# STM32MP157 register map
File version: 1.7
CPU: CM4 r0p1, little endian, no MPU, FPU, 4 interrupt priority bits
Registers are 32-bit, read-write, reset 0x0 unless marked. A register's access mark holds for its fields unless they carry their own. Offsets are from the block's base; [hi:lo] are bit positions; {n}, {i} and the like mark numbered series.

## GPIOA
Base 0x50002000
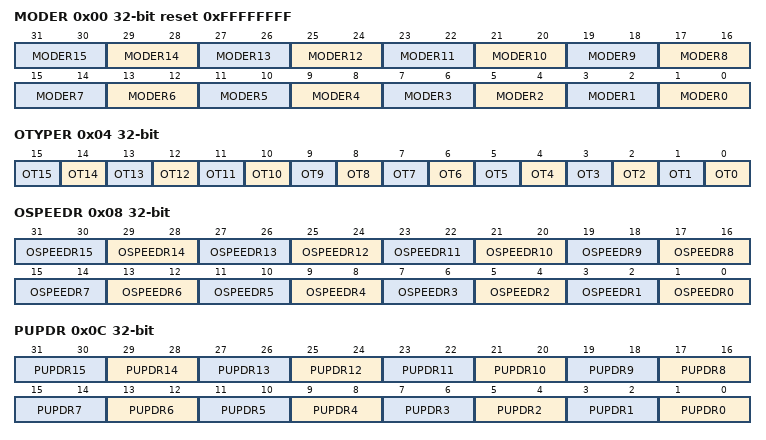
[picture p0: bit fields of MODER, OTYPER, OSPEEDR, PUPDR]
0x00 MODER reset 0xFFFFFFFF — GPIO port mode register
  [2n+1:2n] MODER{n} (n=0..15) — Port x configuration pin {n}
    0=Input mode (reset state); 1=Output (General purpose output mode); 2=Alternate function mode; 3=Analog mode
0x04 OTYPER — GPIO port output type register
  [n] OT{n} (n=0..15) — Port x configuration pin {n}
    0=PushPull (Output push-pull (reset state)); 1=OpenDrain (Output open-drain)
0x08 OSPEEDR — GPIO port output speed register
  [2n+1:2n] OSPEEDR{n} (n=0..15) — Port x configuration pin {n}
    0=LowSpeed; 1=MediumSpeed; 2=HighSpeed; 3=VeryHighSpeed
0x0C PUPDR — GPIO port pull-up/pull-down register
  [2n+1:2n] PUPDR{n} (n=0..15) — Port x configuration pin {n}
    0=Floating (No pull-up, pull-down); 1=PullUp; 2=PullDown
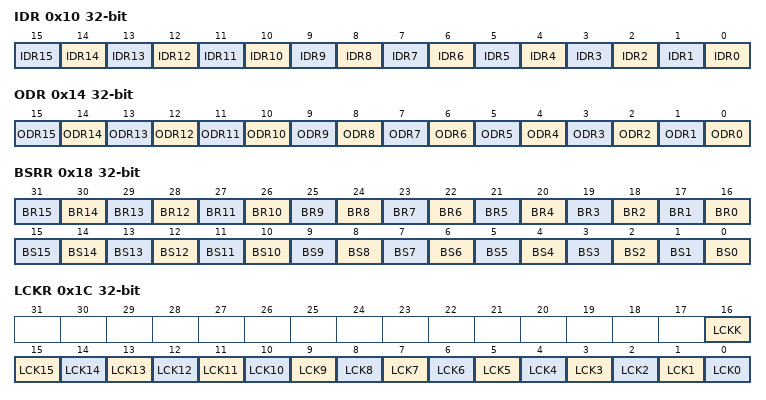
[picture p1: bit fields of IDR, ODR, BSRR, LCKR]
0x10 IDR ro — GPIO port input data register
  [n] IDR{n} (n=0..15) — Port input data pin {n}
    0=Low (Input is logic low); 1=High (Input is logic high)
0x14 ODR — GPIO port output data register
  [n] ODR{n} (n=0..15) — Port output data pin {n}
    0=Low (Set output to logic low); 1=High (Set output to logic high)
0x18 BSRR wo — GPIO port bit set/reset register
  [n+16] BR{n} (n=0..15) — Port x reset pin {n}
    1=Resets the corresponding ODRx bit
  [n] BS{n} (n=0..15) — Port x set pin {n}
    1=Set (Sets the corresponding ODRx bit)
0x1C LCKR — This register is used to lock the configuration of the port bits when a correct write sequence is applied to bit 16 (LCKK). The value of bits [15:0] is used to lock the configuration of the GPIO. During the write sequence, the value of LCKR[15:0] must not change. When the LOCK sequence has been applied on a port bit, the value of this port bit can no longer be modified until the next MCU reset or peripheral reset. A specific write sequence is used to write to the GPIOx_LCKR register. Only word access (32-bit long) is allowed during this locking sequence. Each lock bit freezes a specific configuration register (control and alternate function registers).
  [16] LCKK
    0=NotActive (Port configuration lock key not active); 1=Active (Port configuration lock key active)
  [n] LCK{n} (n=0..15) — Port x lock pin {n}
    0=Unlocked (Port configuration not locked); 1=Locked (Port configuration locked)
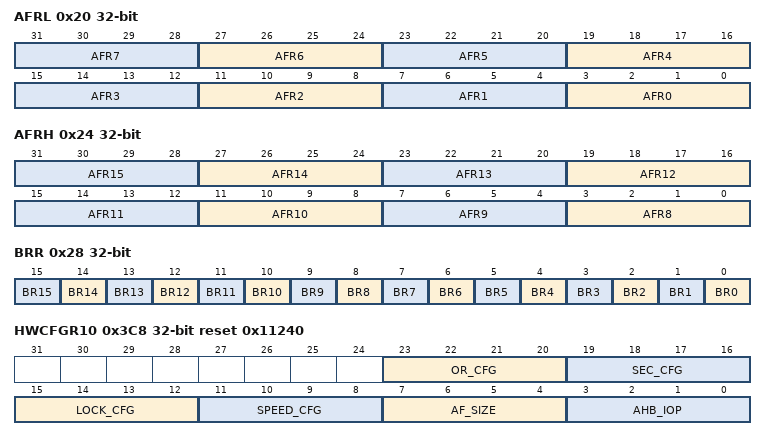
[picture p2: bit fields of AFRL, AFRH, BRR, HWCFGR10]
0x20 AFRL — GPIO alternate function low register
  [4n+3:4n] AFR{n} (n=0..7) — AFR{n}
    {v}=AF{v} (v=0..15)
0x24 AFRH — GPIO alternate function high register
  [4n-29:4n-32] AFR{n} (n=8..15) — AFR{n}
    {v}=AF{v} (v=0..15)
0x28 BRR wo — GPIO port bit reset register
  [n] BR{n} (n=0..15) — Port x reset pin {n}
    0=No action on the corresponding ODx bit; 1=Reset the ODx bit
0x3C8 HWCFGR10 ro reset 0x11240 — For GPIOA, B, C, D, E, F, G, H, I, J and GPIOK: For GPIOZ:
  [23:20] OR_CFG, [19:16] SEC_CFG, [15:12] LOCK_CFG, [11:8] SPEED_CFG, [7:4] AF_SIZE, [3:0] AHB_IOP
0x3CC HWCFGR9 ro reset 0xFF — For GPIOA, B, C, D, E, F, G, H, I, and GPIOJ: For GPIOK and GPIOZ:
  [15:0] EN_IO
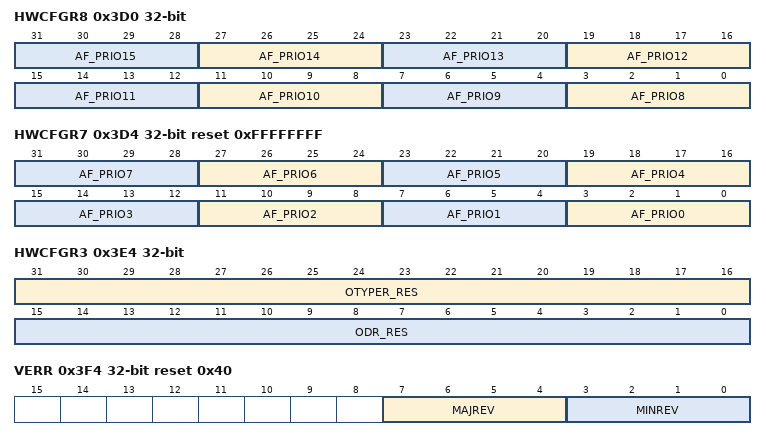
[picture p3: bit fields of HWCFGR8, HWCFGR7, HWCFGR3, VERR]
0x3D0 HWCFGR8 ro — For GPIOA, B, C, D, E, F, G, H, I, and GPIOJ: For GPIOK and GPIOZ:
  [4n-29:4n-32] AF_PRIO{n} (n=8..15)
0x3D4 HWCFGR7 ro reset 0xFFFFFFFF — GPIO hardware configuration register 7
  [4n+3:4n] AF_PRIO{n} (n=0..7)
0x3D8 HWCFGR6 ro reset 0xFFFFFFFF — GPIO hardware configuration register 6
  [31:0] MODER_RES
0x3DC HWCFGR5 ro — GPIO hardware configuration register 5
  [31:0] PUPDR_RES
0x3E0 HWCFGR4 ro — GPIO hardware configuration register 4
  [31:0] OSPEED_RES
0x3E4 HWCFGR3 ro — GPIO hardware configuration register 3
  [31:16] OTYPER_RES, [15:0] ODR_RES
0x3E8 HWCFGR2 ro — GPIO hardware configuration register 2
  [31:0] AFRL_RES
0x3EC HWCFGR1 ro — GPIO hardware configuration register 1
  [31:0] AFRH_RES
0x3F0 HWCFGR0 ro — GPIO hardware configuration register 0
  [15:0] OR_RES
0x3F4 VERR ro reset 0x40 — GPIO version register
  [7:4] MAJREV, [3:0] MINREV
0x3F8 IPIDR ro reset 0xF0002 — GPIO identification register
0x3FC SIDR ro reset 0xA3C5DD01 — GPIO size identification register

## GPIOB
Base 0x50003000
Same registers: GPIOC 0x50004000, GPIOD 0x50005000, GPIOE 0x50006000, GPIOF 0x50007000, GPIOG 0x50008000, GPIOH 0x50009000, GPIOI 0x5000A000
Registers as GPIOA; these are added or differ:
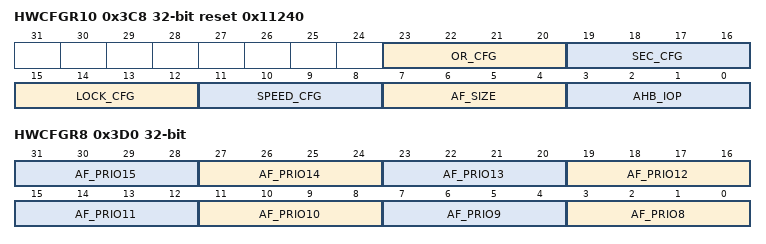
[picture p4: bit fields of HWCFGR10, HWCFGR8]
0x3C8 HWCFGR10 ro reset 0x11240 — For GPIOA, B, C, D, E, F, G, H, I, J and GPIOK: For GPIOZ:
  [23:20] OR_CFG, [19:16] SEC_CFG, [15:12] LOCK_CFG, [11:8] SPEED_CFG, [7:4] AF_SIZE, [3:0] AHB_IOP
0x3CC HWCFGR9 ro reset 0xFF — For GPIOA, B, C, D, E, F, G, H, I, and GPIOJ: For GPIOK and GPIOZ:
  [15:0] EN_IO
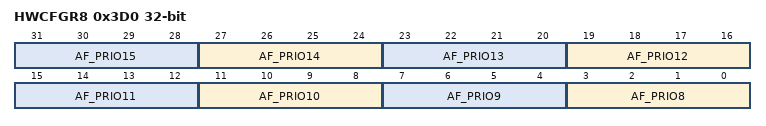
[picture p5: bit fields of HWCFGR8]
0x3D0 HWCFGR8 ro — For GPIOA, B, C, D, E, F, G, H, I, and GPIOJ: For GPIOK and GPIOZ:
  [4n-29:4n-32] AF_PRIO{n} (n=8..15)

## GPIOJ
Base 0x5000B000
Registers as GPIOB; these are added or differ:
0x3CC HWCFGR9 ro reset 0xFF — For GPIOA, B, C, D, E, F, G, H, I, and GPIOJ: For GPIOK and GPIOZ:
  [15:0] EN_IO
0x3D0 HWCFGR8 ro — For GPIOA, B, C, D, E, F, G, H, I, and GPIOJ: For GPIOK and GPIOZ:
  [4n-29:4n-32] AF_PRIO{n} (n=8..15)

## GPIOK
Base 0x5000C000
Registers as GPIOA; these are added or differ:
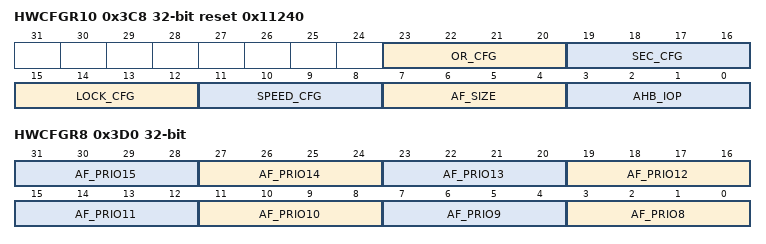
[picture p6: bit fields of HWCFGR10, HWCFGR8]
0x3C8 HWCFGR10 ro reset 0x11240 — For GPIOA, B, C, D, E, F, G, H, I, J and GPIOK: For GPIOZ:
  [23:20] OR_CFG, [19:16] SEC_CFG, [15:12] LOCK_CFG, [11:8] SPEED_CFG, [7:4] AF_SIZE, [3:0] AHB_IOP
0x3CC HWCFGR9 ro reset 0xFF — For GPIOA, B, C, D, E, F, G, H, I, and GPIOJ: For GPIOK and GPIOZ:
  [15:0] EN_IO
0x3D0 HWCFGR8 ro — For GPIOA, B, C, D, E, F, G, H, I, and GPIOJ: For GPIOK and GPIOZ:
  [4n-29:4n-32] AF_PRIO{n} (n=8..15)
